AUTOSAR XML (schema 4-2-2)
package /Components
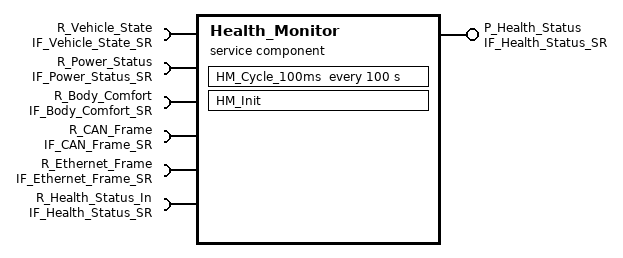
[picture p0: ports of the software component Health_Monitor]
  service sw component type Health_Monitor
    provide port P_Health_Status: provided-interface=IF_Health_Status_SR
    6 x require port:
      R_Vehicle_State: required-interface=IF_Vehicle_State_SR
      R_Power_Status: required-interface=IF_Power_Status_SR
      R_Body_Comfort: required-interface=IF_Body_Comfort_SR
      R_CAN_Frame: required-interface=IF_CAN_Frame_SR
      R_Ethernet_Frame: required-interface=IF_Ethernet_Frame_SR
      R_Health_Status_In: required-interface=IF_Health_Status_SR
    behavior Health_Monitor_InternalBehavior
      init event HM_InitEvent: start-on-event=HM_Init
      timing event HM_Cyclic_100ms: start-on-event=HM_Cycle_100ms, period=100
      runnable HM_Init
        data-send-points:
          access Send_Initial_ECU_Health: accessed-variable=P_Health_Status.ecu_health
          access Send_Initial_Temperature: accessed-variable=P_Health_Status.temperature
          access Send_Initial_Voltage: accessed-variable=P_Health_Status.voltage
      runnable HM_Cycle_100ms: minimum-start-interval=100
        data-read-access:
          11 x access:
            Read_Vehicle_Speed: accessed-variable=R_Vehicle_State.vehicle_speed
            Read_Yaw_Rate: accessed-variable=R_Vehicle_State.yaw_rate
            Read_SOC: accessed-variable=R_Power_Status.soc
            Read_Power_Available: accessed-variable=R_Power_Status.power_available
            Read_Thermal_Derate: accessed-variable=R_Power_Status.thermal_derate
            Read_Link_Status: accessed-variable=R_Ethernet_Frame.link_status
            Read_CAN_Bus_Status: accessed-variable=R_CAN_Frame.can_bus_status
            Read_ECU_Temperature: accessed-variable=R_Health_Status_In.temperature
            Read_ECU_Voltage: accessed-variable=R_Health_Status_In.voltage
            Read_Fault_Code: accessed-variable=R_Health_Status_In.fault_code
            Read_Ambient_Light_Level: accessed-variable=R_Body_Comfort.ambient_light_level
        data-send-points:
          4 x access:
            Send_ECU_Health: accessed-variable=P_Health_Status.ecu_health
            Send_Temperature: accessed-variable=P_Health_Status.temperature
            Send_Voltage: accessed-variable=P_Health_Status.voltage
            Send_Fault_Code: accessed-variable=P_Health_Status.fault_code
